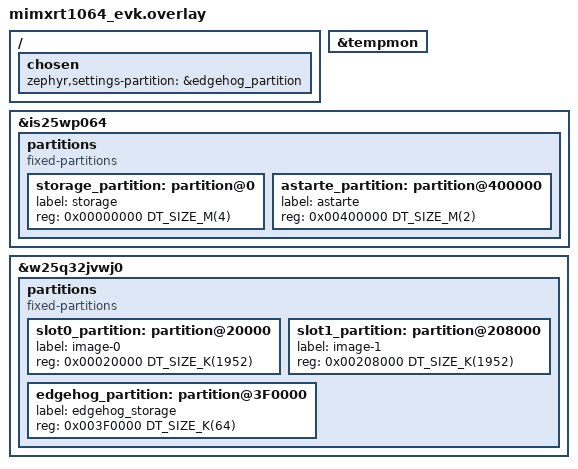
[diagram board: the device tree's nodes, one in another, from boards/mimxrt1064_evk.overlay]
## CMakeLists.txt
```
# (C) Copyright 2025, SECO Mind Srl
#
# SPDX-License-Identifier: Apache-2.0

function(concat_if_exists FILE_PATH STRING_NAME)
    # Check if the file exists
    file(GLOB FILE_TO_ADD ${FILE_PATH})

    # If the file exists, add it to the list
    if(EXISTS ${FILE_TO_ADD})
        set(${STRING_NAME} "${${STRING_NAME}};${FILE_PATH}" PARENT_SCOPE)
    endif()
endfunction()

cmake_minimum_required(VERSION 3.20.0)

# add the sample specific private configuration
concat_if_exists(${CMAKE_SOURCE_DIR}/private.conf EXTRA_CONF_FILE)

find_package(Zephyr REQUIRED HINTS $ENV{ZEPHYR_BASE})
project(cpu_metrics_app)

test_sysbuild()

# create source files list
FILE(GLOB app_common_sources ${CMAKE_CURRENT_LIST_DIR}/src/*.c)
target_sources(app PRIVATE ${app_common_sources})
target_include_directories(app PRIVATE ${CMAKE_CURRENT_LIST_DIR}/include)

# add generated sources and includes for the interfaces
FILE(GLOB app_interfaces_sources ${CMAKE_CURRENT_LIST_DIR}/interfaces/*.c)
target_sources(app PRIVATE ${app_interfaces_sources})
target_include_directories(app PRIVATE ${CMAKE_CURRENT_LIST_DIR}/interfaces)
```

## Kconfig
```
menu "Zephyr"
source "Kconfig.zephyr"
endmenu

menu "CPU metrics sample application"

config ASTARTE_DEVICE_ID
	string "Astarte device ID"
    default ""
	help
	  Device ID to be used to connect to Astarte.

config ASTARTE_CREDENTIAL_SECRET
    string "Astarte credential secret"
    default ""
    help
        The credential secret to be used to connect to Astarte.

config SAMPLE_DURATION_SECONDS
    int "Sample maximum duration (s)"
    default 0
    help
        Use this setting to change for how long the sample will run.
        When set to 0 the sample will run indefinitely.

endmenu

module = APP
module-str = APP
source "subsys/logging/Kconfig.template.log_config"
```

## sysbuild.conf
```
# (C) Copyright 2025, SECO Mind Srl
#
# SPDX-License-Identifier: Apache-2.0

SB_CONFIG_BOOTLOADER_MCUBOOT=y
SB_CONFIG_MCUBOOT_MODE_OVERWRITE_ONLY=y
```

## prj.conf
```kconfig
# (C) Copyright 2025, SECO Mind Srl
#
# SPDX-License-Identifier: Apache-2.0
#
# This is a Kconfig fragment which can be used to enable debug-related options
# in the application. See the README for more details.

# Enable logging with floating point support
CONFIG_LOG=y
CONFIG_CBPRINTF_FP_SUPPORT=y

# Increased stack size
CONFIG_MAIN_STACK_SIZE=4096

# Enable base64 encoding and decoding
CONFIG_BASE64=y

# Enable system hashmaps
CONFIG_SYS_HASH_MAP=y
CONFIG_SYS_HASH_FUNC32=y

# Enable JSON library
CONFIG_JSON_LIBRARY=y

# Enable entropy generator
CONFIG_ENTROPY_GENERATOR=y

# DNS resolver
CONFIG_DNS_RESOLVER=y
CONFIG_DNS_SERVER_IP_ADDRESSES=y
CONFIG_DNS_SERVER1="8.8.8.8" # Google DNS

# MbedTLS
CONFIG_MBEDTLS=y
CONFIG_MBEDTLS_BUILTIN=y
CONFIG_MBEDTLS_ENABLE_HEAP=y
# 55kB is the max absolute value, could be set much lower
CONFIG_MBEDTLS_HEAP_SIZE=95000
# 16384 is the max absolute value, could be set much lower
CONFIG_MBEDTLS_SSL_MAX_CONTENT_LEN=16384
CONFIG_MBEDTLS_PEM_CERTIFICATE_FORMAT=y
CONFIG_MBEDTLS_PK_WRITE_C=y # Required for PEM writing
CONFIG_MBEDTLS_ENTROPY_C=y
CONFIG_MBEDTLS_ENTROPY_POLL_ZEPHYR=y
CONFIG_MBEDTLS_TLS_VERSION_1_2=y
CONFIG_MBEDTLS_CIPHER=y
CONFIG_MBEDTLS_CIPHER_ALL_ENABLED=y
CONFIG_MBEDTLS_SERVER_NAME_INDICATION=y
CONFIG_MBEDTLS_KEY_EXCHANGE_ALL_ENABLED=y
CONFIG_MBEDTLS_HASH_ALL_ENABLED=y
CONFIG_MBEDTLS_CTR_DRBG_ENABLED=y
CONFIG_MBEDTLS_HMAC_DRBG_ENABLED=y
CONFIG_MBEDTLS_CHACHAPOLY_AEAD_ENABLED=y
CONFIG_MBEDTLS_ECDH_C=y
CONFIG_MBEDTLS_ECDSA_C=y
CONFIG_MBEDTLS_ECJPAKE_C=y
CONFIG_MBEDTLS_ECP_C=y
CONFIG_MBEDTLS_ECP_ALL_ENABLED=y
CONFIG_MBEDTLS_GENPRIME_ENABLED=y
CONFIG_MBEDTLS_PKCS5_C=y
CONFIG_MBEDTLS_X509_CRL_PARSE_C=y
CONFIG_MBEDTLS_X509_CSR_PARSE_C=y
CONFIG_MBEDTLS_X509_CSR_WRITE_C=y

# Enable networking
CONFIG_NETWORKING=y

# Sockets
CONFIG_NET_SOCKETS=y
CONFIG_NET_SOCKETS_POLL_MAX=4
CONFIG_NET_SOCKETS_SOCKOPT_TLS=y

# Use DHCP for IPv4 and IPv6
CONFIG_NET_DHCPV4=y
CONFIG_NET_DHCPV6=y

# Generic networking options
CONFIG_NET_TX_STACK_SIZE=4096
CONFIG_NET_RX_STACK_SIZE=4096
CONFIG_NET_PKT_RX_COUNT=20
CONFIG_NET_PKT_TX_COUNT=20
CONFIG_NET_BUF_RX_COUNT=40
CONFIG_NET_BUF_TX_COUNT=40
CONFIG_NET_MAX_CONTEXTS=20
CONFIG_NET_MGMT=y
CONFIG_NET_MGMT_EVENT=y
CONFIG_NET_IPV4=y
CONFIG_NET_IPV6=y
CONFIG_NET_TCP=y

# Enable HTTP client
CONFIG_HTTP_CLIENT=y

# MQTT options
CONFIG_MQTT_LIB=y
CONFIG_MQTT_LIB_TLS=y
CONFIG_MQTT_KEEPALIVE=60

# Enable flash
CONFIG_FLASH=y
CONFIG_FLASH_MAP=y
CONFIG_FLASH_PAGE_LAYOUT=y

# Enable NVS
CONFIG_NVS=y
CONFIG_NVS_LOG_LEVEL_WRN=y

# Astarte device SDK
CONFIG_ASTARTE_DEVICE_SDK=y
CONFIG_ASTARTE_DEVICE_SDK_HOSTNAME="."
CONFIG_ASTARTE_DEVICE_SDK_REALM_NAME="."
# The two certificate tags are the same as the root CA is the same for Astarte API and MQTT broker.
CONFIG_ASTARTE_DEVICE_SDK_HTTPS_CA_CERT_TAG=1
CONFIG_ASTARTE_DEVICE_SDK_MQTTS_CA_CERT_TAG=1
CONFIG_ASTARTE_DEVICE_SDK_CLIENT_CERT_TAG=2
CONFIG_ASTARTE_DEVICE_SDK_PAIRING_JWT=""
CONFIG_ASTARTE_DEVICE_SDK_PERMANENT_STORAGE=y

# Configure the name of the binary
# This will also be used to identify the edgehog image
CONFIG_KERNEL_BIN_NAME="sample-edgehog-app"

# Edgehog depends on
CONFIG_IMG_MANAGER=y
CONFIG_STREAM_FLASH=y
CONFIG_REBOOT=y

# Edgehog device
CONFIG_EDGEHOG_DEVICE=y
CONFIG_EDGEHOG_DEVICE_CA_CERT_OTA_TAG=3
CONFIG_EDGEHOG_DEVICE_ZBUS_OTA_EVENT=y

# System info interface data
CONFIG_EDGEHOG_DEVICE_PART_NUMBER=""
CONFIG_EDGEHOG_DEVICE_SERIAL_NUMBER=""

# Sample configuration
CONFIG_ASTARTE_DEVICE_ID="......................"
CONFIG_ASTARTE_CREDENTIAL_SECRET="."

CONFIG_DNS_RESOLVER_AI_MAX_ENTRIES=4
CONFIG_NET_SOCKETS_TLS_MAX_CONTEXTS=4

CONFIG_THREAD_MONITOR=y
CONFIG_INIT_STACKS=y
CONFIG_THREAD_STACK_INFO=y

CONFIG_ZVFS_OPEN_MAX=16

CONFIG_POSIX_TIMERS=y
CONFIG_SNTP=y
CONFIG_POSIX_CLOCK=y # deprecated but needed for the config below
CONFIG_NET_CONFIG_CLOCK_SNTP_INIT=y
CONFIG_NET_CONFIG_SNTP_INIT_SERVER="0.pool.ntp.org"
CONFIG_NET_CONFIG_SNTP_INIT_TIMEOUT=3000

# Enable the settings
CONFIG_SETTINGS=y

# Activate Zbus
CONFIG_ZBUS=y

# Configuration for the CPU temperature sensor
CONFIG_SENSOR=y

# Configuration for the collection of CPU statistics
CONFIG_THREAD_RUNTIME_STATS=y
CONFIG_SCHED_THREAD_USAGE=y
CONFIG_SCHED_THREAD_USAGE_ALL=y
CONFIG_SCHED_THREAD_USAGE_ANALYSIS=y
CONFIG_SCHED_THREAD_USAGE_AUTO_ENABLE=y
```

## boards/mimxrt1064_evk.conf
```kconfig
# (C) Copyright 2025, SECO Mind Srl
#
# SPDX-License-Identifier: Apache-2.0

# Ethernet settings
CONFIG_NET_L2_ETHERNET=y
CONFIG_NET_L2_ETHERNET_MGMT=y

CONFIG_EDGEHOG_DEVICE_USE_EDGEHOG_PARTITION=y

CONFIG_LOG_MODE_DEFERRED=y
CONFIG_LOG_BUFFER_SIZE=32768
```

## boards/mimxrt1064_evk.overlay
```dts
/*
 * (C) Copyright 2025, SECO Mind Srl
 *
 * SPDX-License-Identifier: Apache-2.0
 */

&tempmon {
	status = "okay";
};

/delete-node/ &storage_partition;

/delete-node/ &slot0_partition;
/delete-node/ &slot1_partition;

&is25wp064 {
	partitions {
		compatible = "fixed-partitions";
		#address-cells = <1>;
		#size-cells = <1>;

		storage_partition: partition@0 {
			label = "storage";
			reg = <0x00000000 DT_SIZE_M(4)>;
		};

		astarte_partition: partition@400000 {
			label = "astarte";
			reg = <0x00400000 DT_SIZE_M(2)>;
		};
	};
};


&w25q32jvwj0 {
	partitions {
		compatible = "fixed-partitions";
		#address-cells = <1>;
		#size-cells = <1>;

		slot0_partition: partition@20000 {
			label = "image-0";
			reg = <0x00020000 DT_SIZE_K(1952)>;
		};

		slot1_partition: partition@208000 {
			label = "image-1";
			reg = <0x00208000 DT_SIZE_K(1952)>;
		};

		/*
		* Reserve the final 64 KiB for edgehog partition
		*/
		edgehog_partition: partition@3F0000 {
			label = "edgehog_storage";
			reg = <0x003F0000 DT_SIZE_K(64)>;
		};
	};
};

/ {
	chosen {
		zephyr,settings-partition = &edgehog_partition;
	};
};
```

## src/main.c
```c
/*
 * (C) Copyright 2025, SECO Mind Srl
 *
 * SPDX-License-Identifier: Apache-2.0
 */

#include <zephyr/device.h>
#include <zephyr/drivers/sensor.h>
#include <zephyr/kernel.h>
#include <zephyr/logging/log.h>
#include <zephyr/net/net_mgmt.h>
#include <zephyr/net/sntp.h>
#include <zephyr/posix/time.h>
LOG_MODULE_REGISTER(cpu_metrics_app, CONFIG_APP_LOG_LEVEL);

#if (!defined(CONFIG_ASTARTE_DEVICE_SDK_DEVELOP_USE_NON_TLS_HTTP)                                  \
    || !defined(CONFIG_ASTARTE_DEVICE_SDK_DEVELOP_USE_NON_TLS_MQTT))
#include <zephyr/net/tls_credentials.h>

#include "ca_certificates.h"
#endif

#include <astarte_device_sdk/device.h>

#ifdef CONFIG_EDGEHOG_DEVICE_ZBUS_OTA_EVENT
#include <edgehog_device/ota_event.h>
#endif
#include <edgehog_device/device.h>
#include <edgehog_device/telemetry.h>
#include <edgehog_device/wifi_scan.h>

#include "eth.h"
#include "generated_interfaces.h"

/************************************************
 * Constants and defines
 ***********************************************/

#define MAIN_THREAD_PERIOD_MS 500
#define EDGEHOG_DEVICE_PERIOD_MS 100
#ifdef CONFIG_EDGEHOG_DEVICE_ZBUS_OTA_EVENT
#define ZBUS_PERIOD_MS 500
#endif

#define HTTP_TIMEOUT_MS (3 * MSEC_PER_SEC)
#define MQTT_FIRST_POLL_TIMEOUT_MS (3 * MSEC_PER_SEC)
#define MQTT_POLL_TIMEOUT_MS 200

#define TELEMETRY_PERIOD_S 5

#define EDGEHOG_DEVICE_THREAD_STACK_SIZE 16384
#define EDGEHOG_DEVICE_THREAD_PRIORITY 0
K_THREAD_STACK_DEFINE(edgehog_device_thread_stack_area, EDGEHOG_DEVICE_THREAD_STACK_SIZE);
static struct k_thread edgehog_device_thread_data;

#ifdef CONFIG_EDGEHOG_DEVICE_ZBUS_OTA_EVENT
#define ZBUS_THREAD_STACK_SIZE 16384
#define ZBUS_THREAD_PRIORITY 0
K_THREAD_STACK_DEFINE(zbus_thread_stack_area, ZBUS_THREAD_STACK_SIZE);
static struct k_thread zbus_thread_data;
#define EDGEHOG_OTA_SUBSCRIBER_NOTIFICATION_QUEUE_SIZE 5
#define EDGEHOG_OTA_OBSERVER_NOTIFY_PRIORITY 5
ZBUS_SUBSCRIBER_DEFINE(edgehog_ota_subscriber, EDGEHOG_OTA_SUBSCRIBER_NOTIFICATION_QUEUE_SIZE);
ZBUS_CHAN_ADD_OBS(edgehog_ota_chan, edgehog_ota_subscriber, EDGEHOG_OTA_OBSERVER_NOTIFY_PRIORITY);
#endif

static const struct device *const die_temp_sensor = DEVICE_DT_GET(DT_ALIAS(die_temp0));

enum device_tread_flags
{
    DEVICE_THREADS_FLAGS_TERMINATION = 1U,
    DEVICE_THREADS_FLAGS_ASTARTE_CONNECTED,
};
static atomic_t device_threads_flags;

static edgehog_device_handle_t edgehog_device;

/************************************************
 * Static functions declaration
 ***********************************************/

/**
 * @brief Initialize System Time
 */
static void system_time_init(void);
/**
 * @brief Entry point for the Astarte device thread.
 *
 * @param arg1 Unused argument.
 * @param arg2 Unused argument.
 * @param arg3 Unused argument.
 */
static void edgehog_device_thread_entry_point(void *arg1, void *arg2, void *arg3);
#ifdef CONFIG_EDGEHOG_DEVICE_ZBUS_OTA_EVENT
/**
 * @brief Entry point for the Zbus reception thread.
 *
 * @param arg1 Unused argument.
 * @param arg2 Unused argument.
 * @param arg3 Unused argument.
 */
static void zbus_thread_entry_point(void *arg1, void *arg2, void *arg3);
#endif
#ifdef CONFIG_EDGEHOG_DEVICE_ZBUS_OTA_EVENT
/**
 * @brief Listen on the Edgehog zbus channel for events.
 *
 * @param timeout The timeout used for listening. In case of a received notification this timeout
 * is also used for reading the message.
 */
static void edgehog_listen_zbus_channel(k_timeout_t timeout);
#endif
/**
 * @brief Callback handler for Astarte connection events.
 *
 * @param event Astarte device connection event.
 */
static void astarte_connection_callback(astarte_device_connection_event_t event);
/**
 * @brief Callback handler for Astarte disconnection events.
 *
 * @param event Astarte device disconnection event.
 */
static void astarte_disconnection_callback(astarte_device_disconnection_event_t event);
/**
 * @brief Timer handler for the CPU statistics.
 *
 * @param dummy Unused.
 */
void cpu_stats_timer_handler(struct k_timer *dummy);

K_TIMER_DEFINE(cpu_usage_timer, cpu_stats_timer_handler, NULL);

/************************************************
 * Global functions definition
 ***********************************************/

// NOLINTNEXTLINE(hicpp-function-size)
int main(void)
{
    LOG_INF("Edgehog device sample");
    LOG_INF("Board: %s", CONFIG_BOARD);

    if (!device_is_ready(die_temp_sensor)) {
        LOG_ERR("sensor: device %s not ready.", die_temp_sensor->name);
        return -ENODEV;
    }

    LOG_INF("Initializing Ethernet driver.");
    if (eth_connect() != 0) {
        LOG_ERR("Connectivity intialization failed!");
        return -1;
    }

    // Add TLS certificate for Astarte if required
#if (!defined(CONFIG_ASTARTE_DEVICE_SDK_DEVELOP_USE_NON_TLS_HTTP)                                  \
    || !defined(CONFIG_ASTARTE_DEVICE_SDK_DEVELOP_USE_NON_TLS_MQTT))
    tls_credential_add(CONFIG_ASTARTE_DEVICE_SDK_HTTPS_CA_CERT_TAG, TLS_CREDENTIAL_CA_CERTIFICATE,
        ca_certificate_root, sizeof(ca_certificate_root));
#endif
    // Add TLS certificate for Edgehog if required
#if !defined(CONFIG_EDGEHOG_DEVICE_DEVELOP_DISABLE_OR_IGNORE_TLS)
    tls_credential_add(CONFIG_EDGEHOG_DEVICE_CA_CERT_OTA_TAG, TLS_CREDENTIAL_CA_CERTIFICATE,
        ota_ca_certificate_root, sizeof(ota_ca_certificate_root));
#endif

    // Initalize the system time
    system_time_init();

    // Spawn a new thread for the Edgehog device
    k_thread_create(&edgehog_device_thread_data, edgehog_device_thread_stack_area,
        K_THREAD_STACK_SIZEOF(edgehog_device_thread_stack_area), edgehog_device_thread_entry_point,
        NULL, NULL, NULL, EDGEHOG_DEVICE_THREAD_PRIORITY, 0, K_NO_WAIT);

    k_timer_start(&cpu_usage_timer, K_SECONDS(5), K_SECONDS(5));

    // Wait for a predefined operational time.
    k_timeout_t finish_timeout = (CONFIG_SAMPLE_DURATION_SECONDS == 0)
        ? K_FOREVER
        : K_SECONDS(CONFIG_SAMPLE_DURATION_SECONDS);
    k_timepoint_t finish_timepoint = sys_timepoint_calc(finish_timeout);
    while (!K_TIMEOUT_EQ(sys_timepoint_timeout(finish_timepoint), K_NO_WAIT)) {
        k_timepoint_t timepoint = sys_timepoint_calc(K_MSEC(MAIN_THREAD_PERIOD_MS));
        // Ensure the connectivity is still present
        eth_poll();
        k_sleep(sys_timepoint_timeout(timepoint));
    }

    k_timer_stop(&cpu_usage_timer);

    // Signal to the Device threads that they should terminate.
    atomic_set_bit(&device_threads_flags, DEVICE_THREADS_FLAGS_TERMINATION);

    // Wait for the Edgehog thread to terminate.
    if (k_thread_join(&edgehog_device_thread_data, K_FOREVER) != 0) {
        LOG_ERR("Failed in waiting for the Edgehog thread to terminate.");
    }

    LOG_INF("Edgehog device sample finished.");
    k_sleep(K_MSEC(MSEC_PER_SEC));

    return 0;
}

/************************************************
 * Static functions definitions
 ***********************************************/

static void system_time_init()
{
#ifdef CONFIG_SNTP
    int ret = 0;
    struct sntp_time now;
    struct timespec tspec;

    ret = sntp_simple(
        CONFIG_NET_CONFIG_SNTP_INIT_SERVER, CONFIG_NET_CONFIG_SNTP_INIT_TIMEOUT, &now);
    if (ret == 0) {
        tspec.tv_sec = (time_t) now.seconds;
        // NOLINTBEGIN(bugprone-narrowing-conversions, hicpp-signed-bitwise,
        // readability-magic-numbers)
        tspec.tv_nsec = ((uint64_t) now.fraction * (1000lu * 1000lu * 1000lu)) >> 32;
        // NOLINTEND(bugprone-narrowing-conversions, hicpp-signed-bitwise,
        // readability-magic-numbers)
        clock_settime(CLOCK_REALTIME, &tspec);
    }
#endif
}

static void edgehog_device_thread_entry_point(void *arg1, void *arg2, void *arg3)
{
    ARG_UNUSED(arg1);
    ARG_UNUSED(arg2);
    ARG_UNUSED(arg3);

    // Configuring the Astarte device used by the Edgehog device to communicate with the cloud
    // Edgehog instance. This device can also be leveraged by the user to send and receive data
    // through Astarte, check out the sample README for more information.
    char cred_secr[ASTARTE_PAIRING_CRED_SECR_LEN + 1] = CONFIG_ASTARTE_CREDENTIAL_SECRET;
    char device_id[ASTARTE_DEVICE_ID_LEN + 1] = CONFIG_ASTARTE_DEVICE_ID;

    const astarte_interface_t *interfaces[] = {
        &com_example_poc_CpuMetrics,
        &com_example_poc_CpuTemp,
    };

    astarte_device_config_t astarte_device_config = { 0 };
    astarte_device_config.http_timeout_ms = HTTP_TIMEOUT_MS;
    astarte_device_config.mqtt_connection_timeout_ms = MQTT_FIRST_POLL_TIMEOUT_MS;
    astarte_device_config.mqtt_poll_timeout_ms = MQTT_POLL_TIMEOUT_MS;
    astarte_device_config.connection_cbk = astarte_connection_callback;
    astarte_device_config.disconnection_cbk = astarte_disconnection_callback;
    astarte_device_config.interfaces = interfaces;
    astarte_device_config.interfaces_size = ARRAY_SIZE(interfaces);
    memcpy(astarte_device_config.cred_secr, cred_secr, sizeof(cred_secr));
    memcpy(astarte_device_config.device_id, device_id, sizeof(device_id));

    edgehog_result_t eres = EDGEHOG_RESULT_OK;

    edgehog_telemetry_config_t telemetry_config = {
        .type = EDGEHOG_TELEMETRY_SYSTEM_STATUS,
        .period_seconds = TELEMETRY_PERIOD_S,
    };
    edgehog_device_config_t edgehog_conf = {
        .astarte_device_config = astarte_device_config,
        .telemetry_config = &telemetry_config,
        .telemetry_config_len = 1,
    };
    eres = edgehog_device_new(&edgehog_conf, &edgehog_device);
    if (eres != EDGEHOG_RESULT_OK) {
        LOG_ERR("Unable to create edgehog device handle");
        goto exit;
    }

    eres = edgehog_device_start(edgehog_device);
    if (eres != EDGEHOG_RESULT_OK) {
        LOG_ERR("Unable to start edgehog device");
        goto exit;
    }

#ifdef CONFIG_EDGEHOG_DEVICE_ZBUS_OTA_EVENT
    // Spawn a new thread for listening on Zbus device
    k_thread_create(&zbus_thread_data, zbus_thread_stack_area,
        K_THREAD_STACK_SIZEOF(zbus_thread_stack_area), zbus_thread_entry_point, NULL, NULL, NULL,
        ZBUS_THREAD_PRIORITY, 0, K_NO_WAIT);
#endif

    while (!atomic_test_bit(&device_threads_flags, DEVICE_THREADS_FLAGS_TERMINATION)) {
        k_timepoint_t timepoint = sys_timepoint_calc(K_MSEC(EDGEHOG_DEVICE_PERIOD_MS));

        eres = edgehog_device_poll(edgehog_device);
        if (eres != EDGEHOG_RESULT_OK) {
            LOG_ERR("Edgehog device poll failure.");
            goto exit;
        }

        k_sleep(sys_timepoint_timeout(timepoint));
    }

    LOG_INF("End of sample, stopping Edgehog.");
    eres = edgehog_device_stop(edgehog_device, K_FOREVER);
    if (eres != EDGEHOG_RESULT_OK) {
        LOG_ERR("Unable to stop the edgehog device");
        goto exit;
    }

    LOG_INF("Edgehog device will now be destroyed.");
    edgehog_device_destroy(edgehog_device);

exit:
    // Ensure to set the thread termination flag
    atomic_set_bit(&device_threads_flags, DEVICE_THREADS_FLAGS_TERMINATION);

#ifdef CONFIG_EDGEHOG_DEVICE_ZBUS_OTA_EVENT
    // Wait for the Zbus thread to terminate.
    if (k_thread_join(&zbus_thread_data, K_SECONDS(10)) != 0) {
        LOG_ERR("Failed in waiting for the Zbus thread to terminate.");
    }
#endif
}

#ifdef CONFIG_EDGEHOG_DEVICE_ZBUS_OTA_EVENT
static void zbus_thread_entry_point(void *arg1, void *arg2, void *arg3)
{
    ARG_UNUSED(arg1);
    ARG_UNUSED(arg2);
    ARG_UNUSED(arg3);

    while (!atomic_test_bit(&device_threads_flags, DEVICE_THREADS_FLAGS_TERMINATION)) {
        edgehog_listen_zbus_channel(K_MSEC(ZBUS_PERIOD_MS));
    }
}
#endif

#ifdef CONFIG_EDGEHOG_DEVICE_ZBUS_OTA_EVENT
static void edgehog_listen_zbus_channel(k_timeout_t timeout)
{
    const struct zbus_channel *chan = NULL;
    edgehog_ota_chan_event_t ota = { 0 };
    if ((zbus_sub_wait(&edgehog_ota_subscriber, &chan, timeout) == 0) && (&edgehog_ota_chan == chan)
        && (zbus_chan_read(chan, &ota, timeout) == 0)) {
        switch (ota.event) {
            case EDGEHOG_OTA_INIT_EVENT:
                LOG_WRN("To subscriber -> EDGEHOG_OTA_INIT_EVENT");
                break;
            case EDGEHOG_OTA_PENDING_REBOOT_EVENT:
                LOG_WRN("To subscriber -> EDGEHOG_OTA_PENDING_REBOOT_EVENT");
                edgehog_ota_chan_event_t ota_chan_event
                    = { .event = EDGEHOG_OTA_CONFIRM_REBOOT_EVENT };
                zbus_chan_pub(&edgehog_ota_chan, &ota_chan_event, K_SECONDS(1));
                break;
            case EDGEHOG_OTA_CONFIRM_REBOOT_EVENT:
                LOG_WRN("To subscriber -> EDGEHOG_OTA_CONFIRM_REBOOT_EVENT");
                break;
            case EDGEHOG_OTA_FAILED_EVENT:
                LOG_WRN("To subscriber -> EDGEHOG_OTA_FAILED_EVENT");
                break;
            case EDGEHOG_OTA_SUCCESS_EVENT:
                LOG_WRN("To subscriber -> EDGEHOG_OTA_SUCCESS_EVENT");
                break;
            default:
                LOG_WRN("To subscriber -> EDGEHOG_OTA_INVALID_EVENT");
        }
    }
}
#endif

static void astarte_connection_callback(astarte_device_connection_event_t event)
{
    ARG_UNUSED(event);
    LOG_INF("Astarte device connected.");
    atomic_set_bit(&device_threads_flags, DEVICE_THREADS_FLAGS_ASTARTE_CONNECTED);
}

static void astarte_disconnection_callback(astarte_device_disconnection_event_t event)
{
    ARG_UNUSED(event);
    LOG_INF("Astarte device disconnected");
    atomic_clear_bit(&device_threads_flags, DEVICE_THREADS_FLAGS_ASTARTE_CONNECTED);
}

void cpu_stats_timer_handler(struct k_timer *dummy)
{
    int rc;

    if (!atomic_test_bit(&device_threads_flags, DEVICE_THREADS_FLAGS_ASTARTE_CONNECTED)) {
        LOG_ERR("Skipping stats transmission, Astarte is not connected.");
        return;
    }

    int64_t timestamp_ms = 0;
    struct timespec tspec;
    rc = clock_gettime(CLOCK_REALTIME, &tspec);
    if (rc != 0) {
        LOG_ERR("Failed getting time.");
    }
    timestamp_ms = (int64_t) tspec.tv_sec * MSEC_PER_SEC + (tspec.tv_nsec / NSEC_PER_MSEC);

    astarte_device_handle_t astarte_device = edgehog_device_get_astarte_device(edgehog_device);

    static uint64_t prev_total_cycles = 0U; // Non idle cycles
    static uint64_t prev_execution_cycles = 0U; // Sum of idle + non idle cycles

    k_thread_runtime_stats_t stats;
    rc = k_thread_runtime_stats_cpu_get(0, &stats);
    if (rc) {
        LOG_ERR("Failed reading CPU stats (%d)", rc);
    } else {
        double cpu_usage = 100.0f * (stats.total_cycles - prev_total_cycles)
            / (stats.execution_cycles - prev_execution_cycles);
        prev_total_cycles = stats.total_cycles;
        prev_execution_cycles = stats.execution_cycles;

        LOG_INF("CPU usage: %.2lf %%", cpu_usage);

        astarte_result_t ares
            = astarte_device_send_individual(astarte_device, com_example_poc_CpuMetrics.name,
                "/loadavg", astarte_data_from_double(cpu_usage), &timestamp_ms);
        if (ares != ASTARTE_RESULT_OK) {
            LOG_ERR("Astarte device transmission failure.");
        }
    }

    rc = sensor_sample_fetch(die_temp_sensor);
    if (rc) {
        LOG_ERR("Failed to fetch temperature sample (%d)", rc);
        return;
    }

    struct sensor_value val;
    rc = sensor_channel_get(die_temp_sensor, SENSOR_CHAN_DIE_TEMP, &val);
    if (rc) {
        LOG_ERR("Failed to get temperature reading (%d)", rc);
        return;
    }

    double die_temp = sensor_value_to_double(&val);
    LOG_INF("CPU Die temperature: %.1f °C", die_temp);

    astarte_result_t ares = astarte_device_send_individual(astarte_device,
        com_example_poc_CpuTemp.name, "/temp", astarte_data_from_double(die_temp), &timestamp_ms);
    if (ares != ASTARTE_RESULT_OK) {
        LOG_ERR("Astarte device transmission failure.");
    }
}
```

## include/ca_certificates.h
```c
/*
 * (C) Copyright 2025, SECO Mind Srl
 *
 * SPDX-License-Identifier: Apache-2.0
 */

#ifndef CA_CERTIFICATES_H
#define CA_CERTIFICATES_H

/* By default only certificates in DER format are supported. If you want to use
 * certificate in PEM format, you can enable support for it in Kconfig.
 */

// Go Daddy Root Certificate Authority - G2
static const unsigned char ca_certificate_root[]
    = { "-----BEGIN CERTIFICATE-----\n"
        "MIIDxTCCAq2gAwIBAgIBADANBgkqhkiG9w0BAQsFADCBgzELMAkGA1UEBhMCVVMx\n"
        "EDAOBgNVBAgTB0FyaXpvbmExEzARBgNVBAcTClNjb3R0c2RhbGUxGjAYBgNVBAoT\n"
        "EUdvRGFkZHkuY29tLCBJbmMuMTEwLwYDVQQDEyhHbyBEYWRkeSBSb290IENlcnRp\n"
        "ZmljYXRlIEF1dGhvcml0eSAtIEcyMB4XDTA5MDkwMTAwMDAwMFoXDTM3MTIzMTIz\n"
        "NTk1OVowgYMxCzAJBgNVBAYTAlVTMRAwDgYDVQQIEwdBcml6b25hMRMwEQYDVQQH\n"
        "EwpTY290dHNkYWxlMRowGAYDVQQKExFHb0RhZGR5LmNvbSwgSW5jLjExMC8GA1UE\n"
        "AxMoR28gRGFkZHkgUm9vdCBDZXJ0aWZpY2F0ZSBBdXRob3JpdHkgLSBHMjCCASIw\n"
        "DQYJKoZIhvcNAQEBBQADggEPADCCAQoCggEBAL9xYgjx+lk09xvJGKP3gElY6SKD\n"
        "E6bFIEMBO4Tx5oVJnyfq9oQbTqC023CYxzIBsQU+B07u9PpPL1kwIuerGVZr4oAH\n"
        "/PMWdYA5UXvl+TW2dE6pjYIT5LY/qQOD+qK+ihVqf94Lw7YZFAXK6sOoBJQ7Rnwy\n"
        "DfMAZiLIjWltNowRGLfTshxgtDj6AozO091GB94KPutdfMh8+7ArU6SSYmlRJQVh\n"
        "GkSBjCypQ5Yj36w6gZoOKcUcqeldHraenjAKOc7xiID7S13MMuyFYkMlNAJWJwGR\n"
        "tDtwKj9useiciAF9n9T521NtYJ2/LOdYq7hfRvzOxBsDPAnrSTFcaUaz4EcCAwEA\n"
        "AaNCMEAwDwYDVR0TAQH/BAUwAwEB/zAOBgNVHQ8BAf8EBAMCAQYwHQYDVR0OBBYE\n"
        "FDqahQcQZyi27/a9BUFuIMGU2g/eMA0GCSqGSIb3DQEBCwUAA4IBAQCZ21151fmX\n"
        "WWcDYfF+OwYxdS2hII5PZYe096acvNjpL9DbWu7PdIxztDhC2gV7+AJ1uP2lsdeu\n"
        "9tfeE8tTEH6KRtGX+rcuKxGrkLAngPnon1rpN5+r5N9ss4UXnT3ZJE95kTXWXwTr\n"
        "gIOrmgIttRD02JDHBHNA7XIloKmf7J6raBKZV8aPEjoJpL1E/QYVN8Gb5DKj7Tjo\n"
        "2GTzLH4U/ALqn83/B2gX2yKQOC16jdFU8WnjXzPKej17CuPKf1855eJ1usV2GDPO\n"
        "LPAvTK33sefOT6jEm0pUBsV/fdUID+Ic/n4XuKxe9tQWskMJDE32p2u0mYRlynqI\n"
        "4uJEvlz36hz1\n"
        "-----END CERTIFICATE-----\n" };

// GTS Root R1
static const unsigned char ota_ca_certificate_root[]
    = { "-----BEGIN CERTIFICATE-----\n"
        "MIIFVzCCAz+gAwIBAgINAgPlk28xsBNJiGuiFzANBgkqhkiG9w0BAQwFADBHMQsw\n"
        "CQYDVQQGEwJVUzEiMCAGA1UEChMZR29vZ2xlIFRydXN0IFNlcnZpY2VzIExMQzEU\n"
        "MBIGA1UEAxMLR1RTIFJvb3QgUjEwHhcNMTYwNjIyMDAwMDAwWhcNMzYwNjIyMDAw\n"
        "MDAwWjBHMQswCQYDVQQGEwJVUzEiMCAGA1UEChMZR29vZ2xlIFRydXN0IFNlcnZp\n"
        "Y2VzIExMQzEUMBIGA1UEAxMLR1RTIFJvb3QgUjEwggIiMA0GCSqGSIb3DQEBAQUA\n"
        "A4ICDwAwggIKAoICAQC2EQKLHuOhd5s73L+UPreVp0A8of2C+X0yBoJx9vaMf/vo\n"
        "27xqLpeXo4xL+Sv2sfnOhB2x+cWX3u+58qPpvBKJXqeqUqv4IyfLpLGcY9vXmX7w\n"
        "Cl7raKb0xlpHDU0QM+NOsROjyBhsS+z8CZDfnWQpJSMHobTSPS5g4M/SCYe7zUjw\n"
        "TcLCeoiKu7rPWRnWr4+wB7CeMfGCwcDfLqZtbBkOtdh+JhpFAz2weaSUKK0Pfybl\n"
        "qAj+lug8aJRT7oM6iCsVlgmy4HqMLnXWnOunVmSPlk9orj2XwoSPwLxAwAtcvfaH\n"
        "szVsrBhQf4TgTM2S0yDpM7xSma8ytSmzJSq0SPly4cpk9+aCEI3oncKKiPo4Zor8\n"
        "Y/kB+Xj9e1x3+naH+uzfsQ55lVe0vSbv1gHR6xYKu44LtcXFilWr06zqkUspzBmk\n"
        "MiVOKvFlRNACzqrOSbTqn3yDsEB750Orp2yjj32JgfpMpf/VjsPOS+C12LOORc92\n"
        "wO1AK/1TD7Cn1TsNsYqiA94xrcx36m97PtbfkSIS5r762DL8EGMUUXLeXdYWk70p\n"
        "aDPvOmbsB4om3xPXV2V4J95eSRQAogB/mqghtqmxlbCluQ0WEdrHbEg8QOB+DVrN\n"
        "VjzRlwW5y0vtOUucxD/SVRNuJLDWcfr0wbrM7Rv1/oFB2ACYPTrIrnqYNxgFlQID\n"
        "AQABo0IwQDAOBgNVHQ8BAf8EBAMCAYYwDwYDVR0TAQH/BAUwAwEB/zAdBgNVHQ4E\n"
        "FgQU5K8rJnEaK0gnhS9SZizv8IkTcT4wDQYJKoZIhvcNAQEMBQADggIBAJ+qQibb\n"
        "C5u+/x6Wki4+omVKapi6Ist9wTrYggoGxval3sBOh2Z5ofmmWJyq+bXmYOfg6LEe\n"
        "QkEzCzc9zolwFcq1JKjPa7XSQCGYzyI0zzvFIoTgxQ6KfF2I5DUkzps+GlQebtuy\n"
        "h6f88/qBVRRiClmpIgUxPoLW7ttXNLwzldMXG+gnoot7TiYaelpkttGsN/H9oPM4\n"
        "7HLwEXWdyzRSjeZ2axfG34arJ45JK3VmgRAhpuo+9K4l/3wV3s6MJT/KYnAK9y8J\n"
        "ZgfIPxz88NtFMN9iiMG1D53Dn0reWVlHxYciNuaCp+0KueIHoI17eko8cdLiA6Ef\n"
        "MgfdG+RCzgwARWGAtQsgWSl4vflVy2PFPEz0tv/bal8xa5meLMFrUKTX5hgUvYU/\n"
        "Z6tGn6D/Qqc6f1zLXbBwHSs09dR2CQzreExZBfMzQsNhFRAbd03OIozUhfJFfbdT\n"
        "6u9AWpQKXCBfTkBdYiJ23//OYb2MI3jSNwLgjt7RETeJ9r/tSQdirpLsQBqvFAnZ\n"
        "0E6yove+7u7Y/9waLd64NnHi/Hm3lCXRSHNboTXns5lndcEZOitHTtNCjv0xyBZm\n"
        "2tIMPNuzjsmhDYAPexZ3FL//2wmUspO8IFgV6dtxQ/PeEMMA3KgqlbbC1j+Qa3bb\n"
        "bP6MvPJwNQzcmRk13NfIRmPVNnGuV/u3gm3c\n"
        "-----END CERTIFICATE-----\n" };

#endif /* CA_CERTIFICATES_H */
```

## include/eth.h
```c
/*
 * (C) Copyright 2025, SECO Mind Srl
 *
 * SPDX-License-Identifier: Apache-2.0
 */

#ifndef ETH_H
#define ETH_H

#include <stdbool.h>
#include <stddef.h>

/**
 * @brief Blocking function to connect the device to internet.
 *
 * @note This is not actually initializing the ethernet module which is intialized by default.
 *
 * @return 0 upon success, -1 otherwise.
 */
int eth_connect(void);

/**
 * @brief Poll the Ethernet driver, ensuring a connection is present.
 *
 * @note This function will block when connectivity is not present.
 */
void eth_poll(void);

#endif /* ETH_H */
```

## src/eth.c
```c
/*
 * (C) Copyright 2025, SECO Mind Srl
 *
 * SPDX-License-Identifier: Apache-2.0
 */

#include "eth.h"

#include <zephyr/kernel.h>
#include <zephyr/logging/log.h>
#include <zephyr/net/ethernet.h>
#include <zephyr/net/ethernet_mgmt.h>
LOG_MODULE_REGISTER(eth, CONFIG_APP_LOG_LEVEL); // NOLINT

/************************************************
 *        Constants, statics and defines        *
 ***********************************************/

// NOLINTBEGIN(cppcoreguidelines-avoid-non-const-global-variables)
static struct net_mgmt_event_callback eth_cb;
static struct net_mgmt_event_callback status_cb;
static struct net_mgmt_event_callback ipv6_cb;
static struct net_mgmt_event_callback ipv4_cb;
static struct net_mgmt_event_callback l4_cb;

static K_SEM_DEFINE(ipv4_address_obtained, 0, 1);
// NOLINTEND(cppcoreguidelines-avoid-non-const-global-variables)

/************************************************
 *       Callbacks declaration/definition       *
 ***********************************************/

static void eth_mgmt_event_handler(
    struct net_mgmt_event_callback *event_cb, uint32_t mgmt_event, struct net_if *iface)
{
    (void) event_cb;
    (void) iface;

    // NOLINTBEGIN(hicpp-signed-bitwise)
    switch (mgmt_event) {
        case NET_EVENT_ETHERNET_CARRIER_ON:
            LOG_DBG("Ethernet event: NET_EVENT_ETHERNET_CARRIER_ON."); // NOLINT
            break;

        case NET_EVENT_ETHERNET_CARRIER_OFF:
            LOG_DBG("Ethernet event: NET_EVENT_ETHERNET_CARRIER_OFF."); // NOLINT
            break;

        case NET_EVENT_ETHERNET_VLAN_TAG_ENABLED:
            LOG_DBG("Ethernet event: NET_EVENT_ETHERNET_VLAN_TAG_ENABLED."); // NOLINT
            break;

        case NET_EVENT_ETHERNET_VLAN_TAG_DISABLED:
            LOG_DBG("Ethernet event: NET_EVENT_ETHERNET_VLAN_TAG_DISABLED."); // NOLINT
            break;

        default:
            LOG_DBG("Status network event: %d.", mgmt_event); // NOLINT
            break;
    }
    // NOLINTEND(hicpp-signed-bitwise)
}

static void status_mgmt_event_handler(
    struct net_mgmt_event_callback *event_cb, uint32_t mgmt_event, struct net_if *iface)
{
    (void) event_cb;
    (void) iface;

    // NOLINTBEGIN(hicpp-signed-bitwise)
    switch (mgmt_event) {
        case NET_EVENT_IF_DOWN:
            LOG_DBG("Network event: NET_EVENT_IF_DOWN."); // NOLINT
            break;

        case NET_EVENT_IF_UP:
            LOG_DBG("Network event: NET_EVENT_IF_UP."); // NOLINT
            break;

        case NET_EVENT_IF_ADMIN_DOWN:
            LOG_DBG("Network event: NET_EVENT_IF_ADMIN_DOWN."); // NOLINT
            break;

        case NET_EVENT_IF_ADMIN_UP:
            LOG_DBG("Network event: NET_EVENT_IF_ADMIN_UP."); // NOLINT
            break;

        default:
            LOG_DBG("Status network event: %d.", mgmt_event); // NOLINT
            break;
    }
    // NOLINTEND(hicpp-signed-bitwise)
}

static void ipv6_mgmt_event_handler(
    struct net_mgmt_event_callback *event_cb, uint32_t mgmt_event, struct net_if *iface)
{
    (void) event_cb;
    (void) iface;

    // NOLINTBEGIN(hicpp-signed-bitwise)
    switch (mgmt_event) {
        case NET_EVENT_IPV6_ADDR_ADD:
            LOG_DBG("IPv6 network event: NET_EVENT_IPV6_ADDR_ADD."); // NOLINT
            break;

        case NET_EVENT_IPV6_ADDR_DEL:
            LOG_DBG("IPv6 network event: NET_EVENT_IPV6_ADDR_DEL."); // NOLINT
            break;

        case NET_EVENT_IPV6_MADDR_ADD:
            LOG_DBG("IPv6 network event: NET_EVENT_IPV6_MADDR_ADD."); // NOLINT
            break;

        case NET_EVENT_IPV6_MADDR_DEL:
            LOG_DBG("IPv6 network event: NET_EVENT_IPV6_MADDR_DEL."); // NOLINT
            break;

        case NET_EVENT_IPV6_PREFIX_ADD:
            LOG_DBG("IPv6 network event: NET_EVENT_IPV6_PREFIX_ADD."); // NOLINT
            break;

        case NET_EVENT_IPV6_PREFIX_DEL:
            LOG_DBG("IPv6 network event: NET_EVENT_IPV6_PREFIX_DEL."); // NOLINT
            break;

        case NET_EVENT_IPV6_MCAST_JOIN:
            LOG_DBG("IPv6 network event: NET_EVENT_IPV6_MCAST_JOIN."); // NOLINT
            break;

        case NET_EVENT_IPV6_MCAST_LEAVE:
            LOG_DBG("IPv6 network event: NET_EVENT_IPV6_MCAST_LEAVE."); // NOLINT
            break;

        case NET_EVENT_IPV6_ROUTER_ADD:
            LOG_DBG("IPv6 network event: NET_EVENT_IPV6_ROUTER_ADD."); // NOLINT
            break;

        case NET_EVENT_IPV6_ROUTER_DEL:
            LOG_DBG("IPv6 network event: NET_EVENT_IPV6_ROUTER_DEL."); // NOLINT
            break;

        case NET_EVENT_IPV6_ROUTE_ADD:
            LOG_DBG("IPv6 network event: NET_EVENT_IPV6_ROUTE_ADD."); // NOLINT
            break;

        case NET_EVENT_IPV6_ROUTE_DEL:
            LOG_DBG("IPv6 network event: NET_EVENT_IPV6_ROUTE_DEL."); // NOLINT
            break;

        case NET_EVENT_IPV6_DAD_SUCCEED:
            LOG_DBG("IPv6 network event: NET_EVENT_IPV6_DAD_SUCCEED."); // NOLINT
            break;

        case NET_EVENT_IPV6_DAD_FAILED:
            LOG_DBG("IPv6 network event: NET_EVENT_IPV6_DAD_FAILED."); // NOLINT
            break;

        case NET_EVENT_IPV6_NBR_ADD:
            LOG_DBG("IPv6 network event: NET_EVENT_IPV6_NBR_ADD."); // NOLINT
            break;

        case NET_EVENT_IPV6_NBR_DEL:
            LOG_DBG("IPv6 network event: NET_EVENT_IPV6_NBR_DEL."); // NOLINT
            break;

        case NET_EVENT_IPV6_DHCP_START:
            LOG_DBG("IPv6 network event: NET_EVENT_IPV6_DHCP_START."); // NOLINT
            break;

        case NET_EVENT_IPV6_DHCP_BOUND:
            LOG_DBG("IPv6 network event: NET_EVENT_IPV6_DHCP_BOUND."); // NOLINT
            break;

        case NET_EVENT_IPV6_DHCP_STOP:
            LOG_DBG("IPv6 network event: NET_EVENT_IPV6_DHCP_STOP."); // NOLINT
            break;

        default:
            LOG_DBG("IPv6 network event: %d.", mgmt_event); // NOLINT
            break;
    }
    // NOLINTEND(hicpp-signed-bitwise)
}

static void ipv4_mgmt_event_handler(
    struct net_mgmt_event_callback *event_cb, uint32_t mgmt_event, struct net_if *iface)
{
    (void) event_cb;
    (void) iface;

    // NOLINTBEGIN(hicpp-signed-bitwise)
    switch (mgmt_event) {
        case NET_EVENT_IPV4_ADDR_ADD:
            LOG_DBG("Network event: NET_EVENT_IPV4_ADDR_ADD."); // NOLINT
            k_sem_give(&ipv4_address_obtained);
            break;

        case NET_EVENT_IPV4_ADDR_DEL:
            LOG_DBG("Network event: NET_EVENT_IPV4_ADDR_DEL."); // NOLINT
            k_sem_take(&ipv4_address_obtained, K_NO_WAIT);
            break;

        case NET_EVENT_IPV4_MADDR_ADD:
            LOG_DBG("Network event: NET_EVENT_IPV4_MADDR_ADD."); // NOLINT
            break;

        case NET_EVENT_IPV4_MADDR_DEL:
            LOG_DBG("Network event: NET_EVENT_IPV4_MADDR_DEL."); // NOLINT
            break;

        case NET_EVENT_IPV4_ROUTER_ADD:
            LOG_DBG("Network event: NET_EVENT_IPV4_ROUTER_ADD."); // NOLINT
            break;

        case NET_EVENT_IPV4_ROUTER_DEL:
            LOG_DBG("Network event: NET_EVENT_IPV4_ROUTER_DEL."); // NOLINT
            break;

        case NET_EVENT_IPV4_DHCP_START:
            LOG_DBG("Network event: NET_EVENT_IPV4_DHCP_START."); // NOLINT
            break;

        case NET_EVENT_IPV4_DHCP_BOUND:
            LOG_DBG("Network event: NET_EVENT_IPV4_DHCP_BOUND."); // NOLINT
            break;

        case NET_EVENT_IPV4_DHCP_STOP:
            LOG_DBG("Network event: NET_EVENT_IPV4_DHCP_STOP."); // NOLINT
            break;

        case NET_EVENT_IPV4_MCAST_JOIN:
            LOG_DBG("Network event: NET_EVENT_IPV4_MCAST_JOIN."); // NOLINT
            break;

        case NET_EVENT_IPV4_MCAST_LEAVE:
            LOG_DBG("Network event: NET_EVENT_IPV4_MCAST_LEAVE."); // NOLINT
            break;

        default:
            LOG_DBG("Network event: %d.", mgmt_event); // NOLINT
            break;
    }
    // NOLINTEND(hicpp-signed-bitwise)
}

static void l4_mgmt_event_handler(
    struct net_mgmt_event_callback *event_cb, uint32_t mgmt_event, struct net_if *iface)
{
    (void) event_cb;
    (void) iface;

    // NOLINTBEGIN(hicpp-signed-bitwise)
    switch (mgmt_event) {
        case NET_EVENT_L4_CONNECTED:
            LOG_DBG("Network event: NET_EVENT_L4_CONNECTED."); // NOLINT
            break;

        case NET_EVENT_L4_DISCONNECTED:
            LOG_DBG("Network event: NET_EVENT_L4_DISCONNECTED."); // NOLINT
            break;

        case NET_EVENT_DNS_SERVER_ADD:
            LOG_DBG("Network event: NET_EVENT_DNS_SERVER_ADD."); // NOLINT
            break;

        case NET_EVENT_DNS_SERVER_DEL:
            LOG_DBG("Network event: NET_EVENT_DNS_SERVER_DEL."); // NOLINT
            break;

        case NET_EVENT_HOSTNAME_CHANGED:
            LOG_DBG("Network event: NET_EVENT_HOSTNAME_CHANGED."); // NOLINT
            break;

        default:
            LOG_DBG("Network event: %d.", mgmt_event); // NOLINT
            break;
    }
    // NOLINTEND(hicpp-signed-bitwise)
}

/************************************************
 * Global functions definition
 ***********************************************/

int eth_connect(void)
{
    LOG_INF("Connecting through ethernet..."); // NOLINT

    // NOLINTBEGIN(hicpp-signed-bitwise, misc-redundant-expression)
    net_mgmt_init_event_callback(&eth_cb, eth_mgmt_event_handler,
        NET_EVENT_ETHERNET_CARRIER_ON | NET_EVENT_ETHERNET_CARRIER_OFF
            | NET_EVENT_ETHERNET_VLAN_TAG_ENABLED | NET_EVENT_ETHERNET_VLAN_TAG_DISABLED);
    net_mgmt_init_event_callback(&status_cb, status_mgmt_event_handler,
        NET_EVENT_IF_DOWN | NET_EVENT_IF_UP | NET_EVENT_IF_ADMIN_DOWN | NET_EVENT_IF_ADMIN_UP);
    net_mgmt_init_event_callback(&ipv6_cb, ipv6_mgmt_event_handler,
        NET_EVENT_IPV6_ADDR_ADD | NET_EVENT_IPV6_ADDR_DEL | NET_EVENT_IPV6_MADDR_ADD
            | NET_EVENT_IPV6_MADDR_DEL | NET_EVENT_IPV6_PREFIX_ADD | NET_EVENT_IPV6_PREFIX_DEL
            | NET_EVENT_IPV6_MCAST_JOIN | NET_EVENT_IPV6_MCAST_LEAVE | NET_EVENT_IPV6_ROUTER_ADD
            | NET_EVENT_IPV6_ROUTER_DEL | NET_EVENT_IPV6_ROUTE_ADD | NET_EVENT_IPV6_ROUTE_DEL
            | NET_EVENT_IPV6_DAD_SUCCEED | NET_EVENT_IPV6_DAD_FAILED | NET_EVENT_IPV6_NBR_ADD
            | NET_EVENT_IPV6_NBR_DEL | NET_EVENT_IPV6_DHCP_START | NET_EVENT_IPV6_DHCP_BOUND
            | NET_EVENT_IPV6_DHCP_STOP);
    net_mgmt_init_event_callback(&ipv4_cb, ipv4_mgmt_event_handler,
        NET_EVENT_IPV4_ADDR_ADD | NET_EVENT_IPV4_ADDR_DEL | NET_EVENT_IPV4_MADDR_ADD
            | NET_EVENT_IPV4_MADDR_DEL | NET_EVENT_IPV4_ROUTER_ADD | NET_EVENT_IPV4_ROUTER_DEL
            | NET_EVENT_IPV4_DHCP_START | NET_EVENT_IPV4_DHCP_BOUND | NET_EVENT_IPV4_DHCP_STOP
            | NET_EVENT_IPV4_MCAST_JOIN | NET_EVENT_IPV4_MCAST_LEAVE);
    net_mgmt_init_event_callback(&l4_cb, l4_mgmt_event_handler,
        NET_EVENT_L4_CONNECTED | NET_EVENT_L4_DISCONNECTED | NET_EVENT_DNS_SERVER_ADD
            | NET_EVENT_DNS_SERVER_DEL | NET_EVENT_HOSTNAME_CHANGED);
    // NOLINTEND(hicpp-signed-bitwise, misc-redundant-expression)

    net_mgmt_add_event_callback(&eth_cb);
    net_mgmt_add_event_callback(&status_cb);
    net_mgmt_add_event_callback(&ipv6_cb);
    net_mgmt_add_event_callback(&ipv4_cb);
    net_mgmt_add_event_callback(&l4_cb);

    struct net_if *iface = net_if_get_default();
    if (!iface) {
        LOG_ERR("Default interface non existant."); // NOLINT
        return -1;
    }

    LOG_INF("Waiting for Ethernet interface to be operational."); // NOLINT
    while (net_if_oper_state(iface) != NET_IF_OPER_UP) {
        k_sleep(K_MSEC(200));
    }

    const struct device *dev = net_if_get_device(iface);
    LOG_INF("Default network interface device name: %s.", dev->name); // NOLINT
    struct ethernet_context *eth_ctx = net_if_l2_data(iface);
    LOG_INF("Ethernet carrier: %s.", eth_ctx->is_net_carrier_up ? "UP" : "DOWN"); // NOLINT
    LOG_INF("Ethernet context is initialized: %s.", eth_ctx->is_init ? "YES" : "NO"); // NOLINT
    enum net_if_oper_state iface_oper_state = net_if_oper_state(iface);
    LOG_INF("Default network interface operational state: %d.", iface_oper_state); // NOLINT

#ifdef CONFIG_NET_DHCPV4
    net_dhcpv4_start(iface);

    LOG_INF("Waiting for an IPv4 address (DHCP)."); // NOLINT
    while (k_sem_count_get(&ipv4_address_obtained) == 0) {
        k_sleep(K_MSEC(200));
    }
#endif

    k_sleep(K_MSEC(500));

    LOG_INF("Ready..."); // NOLINT

    return 0;
}

void eth_poll(void)
{
    struct net_if *iface = net_if_get_default();
    if (!iface) {
        LOG_ERR("Default interface non existant."); // NOLINT
        return;
    }

    // Check if connected
    while (net_if_oper_state(iface) != NET_IF_OPER_UP) {
        LOG_WRN("Ethernet interface is non operational."); // NOLINT
        k_sleep(K_SECONDS(1));
    }

// Restart DHCP if required.
#ifdef CONFIG_NET_DHCPV4
    if (k_sem_count_get(&ipv4_address_obtained) == 0) {
        LOG_WRN("Missing IPv4 address."); // NOLINT
        net_dhcpv4_restart(iface);
        LOG_INF("Waiting for an IPv4 address (DHCP)."); // NOLINT
        while (k_sem_count_get(&ipv4_address_obtained) == 0) {
            k_sleep(K_MSEC(200));
        }
        LOG_INF("Ready..."); // NOLINT
    }
#endif

    k_sleep(K_MSEC(500));
}
```
